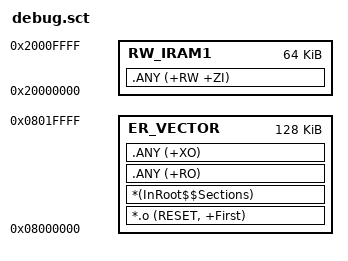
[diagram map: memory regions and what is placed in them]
; *************************************************************
; *** Scatter-Loading Description File - debug 调试用       ***
; *************************************************************
;
; Flash 布局 (与 updata_app 一致, 调试所见即所得):
;   0x0800F800  APP_INFO     固件版本 + 设备密钥 + 预留 (128B)
;   0x08010000  App          固件主体
;

LR_VECTOR 0x08000000 0x00020000  {
  ER_VECTOR 0x08000000 0x00020000  {
    *.o (RESET, +First)
    *(InRoot$$Sections)
	.ANY (+RO)
    .ANY (+XO)
  }
  RW_IRAM1 0x20000000 0x00010000  {
    .ANY (+RW +ZI)
  }  
}

